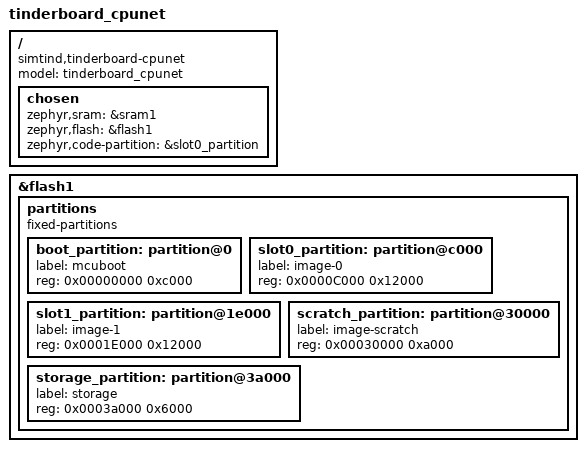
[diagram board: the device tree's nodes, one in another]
// Copyright (c) 2022 Nordic Semiconductor ASA
// SPDX-License-Identifier: Apache-2.0

/dts-v1/;
#include <nordic/nrf5340_cpunet_qkaa.dtsi>

/ {
	model = "tinderboard_cpunet";
	compatible = "simtind,tinderboard-cpunet";

	chosen {
		zephyr,sram = &sram1;
		zephyr,flash = &flash1;
		zephyr,code-partition = &slot0_partition;
	};
};

&flash1 {
	partitions {
		compatible = "fixed-partitions";
		#address-cells = <1>;
		#size-cells = <1>;

		boot_partition: partition@0 {
			label = "mcuboot";
			reg = <0x00000000 0xc000>;
		};
		slot0_partition: partition@c000 {
			label = "image-0";
			reg = <0x0000C000 0x12000>;
		};
		slot1_partition: partition@1e000 {
			label = "image-1";
			reg = <0x0001E000 0x12000>;
		};
		scratch_partition: partition@30000 {
			label = "image-scratch";
			reg = <0x00030000 0xa000>;
		};
		storage_partition: partition@3a000 {
			label = "storage";
			reg = <0x0003a000 0x6000>;
		};
	};
};

#include "tinderboard_shared_sram_planning_conf.dts"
